# STM32F378xx register map
File version: 1.0
Registers are 32-bit, read-write, reset 0x0 unless marked. A register's access mark holds for its fields unless they carry their own. Offsets are from the block's base; [hi:lo] are bit positions; {n}, {i} and the like mark numbered series.

## CEC — Consumer Electronics Control
Base 0x40007800
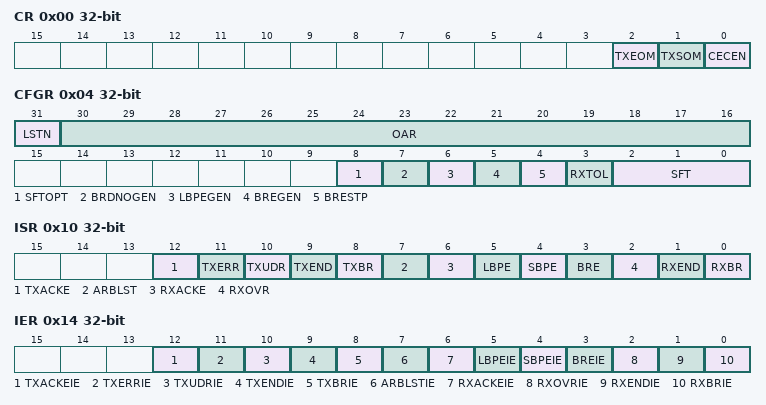
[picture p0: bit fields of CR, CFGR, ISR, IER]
0x00 CR — CEC control register
  [2] TXEOM — CEC Tx End Of Message
  [1] TXSOM — CEC Tx Start Of Message
  [0] CECEN — CEC Enable
0x04 CFGR — CEC configuration register
  [31] LSTN — CEC Listen mode
  [30:16] OAR — CEC Own Address
  [8] SFTOPT — CEC Signal Free Time optional
  [7] BRDNOGEN — CEC Broadcast No error generation
  [6] LBPEGEN — CEC Long Bit Period Error generation
  [5] BREGEN — CEC Bit Rising Error generation
  [4] BRESTP — CEC Rx Stop
  [3] RXTOL — CEC Tolerance
  [2:0] SFT — CEC Signal Free Time
0x08 TXDR — CEC Tx data register
  [7:0] TXD — CEC Tx Data
0x0C RXDR — CEC Rx Data Register
  [7:0] RXD — CEC Rx Data
0x10 ISR — CEC Interrupt and Status Register
  [12] TXACKE — CEC Tx Missing Acknowledge
  [11] TXERR — CEC Tx-Error
  [10] TXUDR — CEC Tx-Buffer Underrun
  [9] TXEND — CEC End of Transmission
  [8] TXBR — CEC Tx Byte Request
  [7] ARBLST — CEC Arbitration Lost
  [6] RXACKE — CEC Rx Missing Acknowledge
  [5] LBPE — CEC Rx Long Bit period Error
  [4] SBPE — CEC Rx Short Bit period Error
  [3] BRE — CEC Rx Bit Rising Error
  [2] RXOVR — CEC Rx-Overrun
  [1] RXEND — CEC End Of Reception
  [0] RXBR — CEC Rx-Byte Received
0x14 IER — CEC interrupt enable register
  [12] TXACKEIE — CEC Tx Missing Acknowledge IT Enable
  [11] TXERRIE — CEC Tx-Error IT Enable
  [10] TXUDRIE — CEC Tx-Buffer Underrun IT Enable
  [9] TXENDIE — CEC End of Transmission IT Enable
  [8] TXBRIE — CEC Tx Byte Request IT Enable
  [7] ARBLSTIE — CEC Arbitration Lost IT Enable
  [6] RXACKEIE — CEC Rx Missing Acknowledge IT Enable
  [5] LBPEIE — CEC Rx Long Bit period Error IT Enable
  [4] SBPEIE — CEC Rx Short Bit period Error IT Enable
  [3] BREIE — CEC Rx Bit Rising Error IT Enable
  [2] RXOVRIE — CEC Rx-Overrun IT Enable
  [1] RXENDIE — CEC End Of Reception IT Enable
  [0] RXBRIE — CEC Rx-Byte Received IT Enable

## SYSCFG — System configuration controller
Base 0x40010000
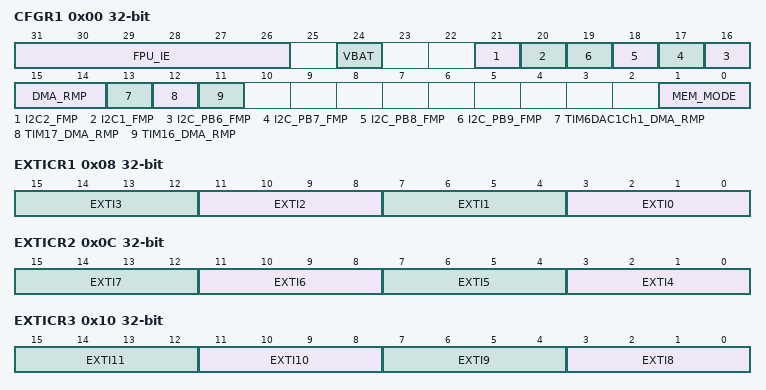
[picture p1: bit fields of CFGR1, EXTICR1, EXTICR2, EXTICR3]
0x00 CFGR1 — SYSCFG configuration register 1
  [31:26] FPU_IE — Floating Point Unit Interrupt Enable
  [24] VBAT — VBAT monitoring
  [21] I2C2_FMP — I2C2 Fast mode plus
  [20] I2C1_FMP — I2C1 Fast mode plus
  [n+10] I2C_PB{n}_FMP (n=6..9) — I2C PB{n} Fast mode plus
  [15:14] DMA_RMP — DMA remap mask
  [13] TIM6DAC1Ch1_DMA_RMP — Timer 6 / DAC1 Ch1 DMA remap
  [12] TIM17_DMA_RMP — Timer 17 DMA remap
  [11] TIM16_DMA_RMP — Timer 16 DMA remap
  [1:0] MEM_MODE — SYSCFG_Memory Remap Config
    0=FLASH; 1=SYSTEMFLASH; 3=SRAM
0x08 EXTICR1 — SYSCFG external interrupt configuration registers
  [4n+3:4n] EXTI{n} (n=0..3) — EXTI {n} configuration
0x0C EXTICR2 — SYSCFG external interrupt configuration registers
  [4n-13:4n-16] EXTI{n} (n=4..7) — EXTI {n} configuration
0x10 EXTICR3 — SYSCFG external interrupt configuration registers
  [4n-29:4n-32] EXTI{n} (n=8..11) — EXTI {n} configuration
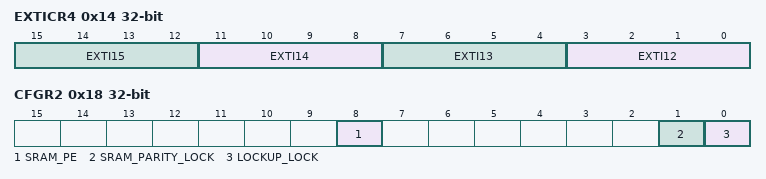
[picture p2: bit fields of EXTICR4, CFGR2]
0x14 EXTICR4 — SYSCFG external interrupt configuration registers
  [4n-45:4n-48] EXTI{n} (n=12..15) — EXTI {n} configuration
0x18 CFGR2 — SYSCFG configuration register 2
  [8] SRAM_PE — SRAM Parity error flag
  [1] SRAM_PARITY_LOCK — Enables and locks the SRAM_PARITY error signal with Break Input of TIMx
  [0] LOCKUP_LOCK — Enables and locks the LOCKUP (Hardfault) output of CortexM4 with Break Input of TIMx

## EXTI — External Interrupt/Event Controller
Base 0x40010400
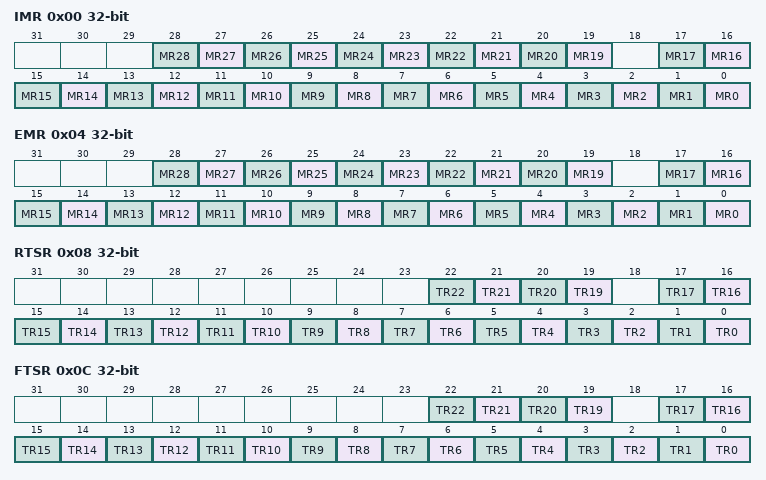
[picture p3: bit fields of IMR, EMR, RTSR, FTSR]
0x00 IMR — EXTI Interrupt mask register
  [n] MR{n} (n=19..28) — Interrupt Mask on line {n}
  [n] MR{n} (n=0..17) — Interrupt Mask on line {n}
0x00 IMR_ALT (alternate view of IMR) — EXTI Interrupt mask register
  [28:0] IM — Interrupt Mask All
0x04 EMR — EXTI Event mask register
  [n] MR{n} (n=19..28) — Event Mask on line {n}
  [n] MR{n} (n=0..17) — Event Mask on line {n}
0x08 RTSR — EXTI Rising trigger selection register
  [n] TR{n} (n=19..22) — Rising trigger event configuration bit of line {n}
  [n] TR{n} (n=0..17) — Rising trigger event configuration bit of line {n}
0x0C FTSR — EXTI Falling trigger selection register
  [n] TR{n} (n=19..22) — Falling trigger event configuration bit of line {n}
  [n] TR{n} (n=0..17) — Falling trigger event configuration bit of line {n}
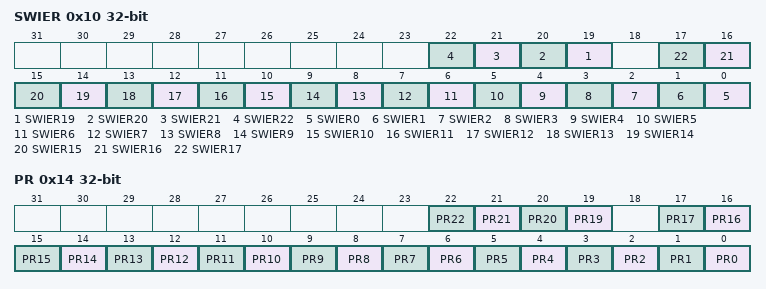
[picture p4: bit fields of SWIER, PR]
0x10 SWIER — EXTI Software interrupt event register
  [n] SWIER{n} (n=19..22) — Software Interrupt on line {n}
  [n] SWIER{n} (n=0..17) — Software Interrupt on line {n}
0x14 PR — EXTI Pending register
  [n] PR{n} (n=19..22) — Pending bit for line {n}
  [n] PR{n} (n=0..17) — Pending bit for line {n}
